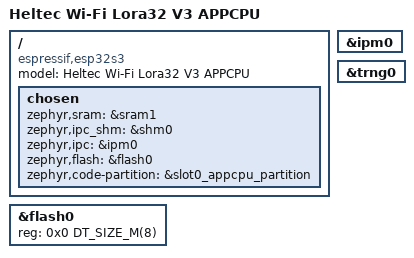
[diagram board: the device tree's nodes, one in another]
/*
 * Copyright (c) 2023 Espressif Systems (Shanghai) Co., Ltd.
 * SPDX-FileCopyrightText: Copyright The Zephyr Project Contributors
 *
 * SPDX-License-Identifier: Apache-2.0
 */
/dts-v1/;

#include <espressif/esp32s3/esp32s3_appcpu.dtsi>
#include <espressif/partitions_0x0_amp_8M.dtsi>

/ {
	model = "Heltec Wi-Fi Lora32 V3 APPCPU";
	compatible = "espressif,esp32s3";

	chosen {
		zephyr,sram = &sram1;
		zephyr,ipc_shm = &shm0;
		zephyr,ipc = &ipm0;
		zephyr,flash = &flash0;
		zephyr,code-partition = &slot0_appcpu_partition;
	};
};

&flash0 {
	reg = <0x0 DT_SIZE_M(8)>;
};

&ipm0 {
	status = "okay";
};

&trng0 {
	status = "okay";
};
